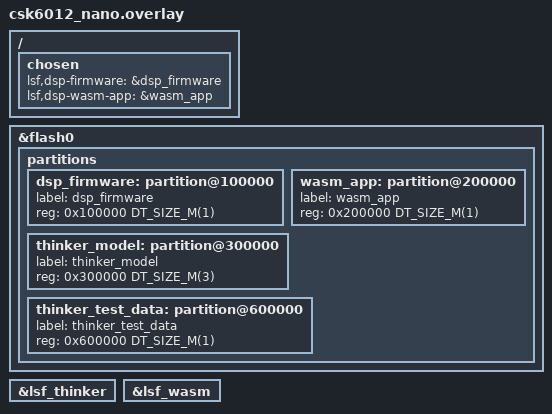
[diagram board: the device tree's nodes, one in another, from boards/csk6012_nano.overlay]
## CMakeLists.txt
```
# Copyright (c) 2023 LISTENAI
# SPDX-License-Identifier: Apache-2.0

cmake_minimum_required(VERSION 3.20.0)

find_package(Zephyr REQUIRED HINTS $ENV{ZEPHYR_BASE})
project(thinker_wasm)

target_sources(app PRIVATE src/main.c)
```

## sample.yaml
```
sample:
  name: thinker_wasm
tests:
  sample.thinker_wasm:
    tags: thinker wasm
```

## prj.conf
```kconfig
CONFIG_HEAP_MEM_POOL_SIZE=204800

CONFIG_CSK_HEAP=y
CONFIG_CSK_HEAP_MEM_POOL_SIZE=40960

CONFIG_FLASH=y
CONFIG_FLASH_MAP=y
CONFIG_FLASH_PAGE_LAYOUT=y

CONFIG_FILE_SYSTEM=y
CONFIG_FILE_SYSTEM_LITTLEFS=y

# CONFIG_CSK6_FLASH_STALL_SECOND_CORE=n
```

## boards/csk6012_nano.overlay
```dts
/*
 * Copyright(c) 2023 LISTENAI
 * SPDX-License-Identifier: Apache-2.0
 */

#include <lsf/lsf.dtsi>

/ {
	chosen {
		lsf,dsp-firmware = &dsp_firmware;
		lsf,dsp-wasm-app = &wasm_app;
	};
};

&flash0 {
	partitions {
		dsp_firmware: partition@100000 {
			label = "dsp_firmware";
			reg = <0x100000 DT_SIZE_M(1)>;
		};

		wasm_app: partition@200000 {
			label = "wasm_app";
			reg = <0x200000 DT_SIZE_M(1)>;
		};

		thinker_model: partition@300000 {
			label = "thinker_model";
			reg = <0x300000 DT_SIZE_M(3)>;
		};

		thinker_test_data: partition@600000 {
			label = "thinker_test_data";
			reg = <0x600000 DT_SIZE_M(1)>;
		};
	};
};

&lsf_thinker {
	status = "okay";
};

&lsf_wasm {
	status = "okay";
};
```

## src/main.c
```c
/*
 * Copyright(c) 2023 LISTENAI
 * SPDX-License-Identifier: Apache-2.0
 */

#include <stdint.h>

#include <zephyr/kernel.h>
#include <zephyr/device.h>
#include <zephyr/storage/flash_map.h>

#include <lsf/services/thinker.h>

#include "apple_input.h"

#define FLASH_ADDR         (DT_REG_ADDR(DT_CHOSEN(zephyr_flash)))
#define THINKER_MODEL_ADDR (FLASH_ADDR + FLASH_AREA_OFFSET(thinker_model))

#define THINKER_TEST_DATA_ADDR    (FLASH_ADDR + FLASH_AREA_OFFSET(thinker_test_data))
#define THINKER_TEST_OUTPUT_COUNT (10)

void main(void)
{
	printk("Hello World! %s\n", CONFIG_BOARD);

	/* 加载 Thinker 模型，注意传入模型的实际字节数 */
	lsf_thinker_set_model((const void *)THINKER_MODEL_ADDR, 436224);
	printk("Model loaded\n");

	int8_t *outputs[THINKER_TEST_OUTPUT_COUNT];
	uint32_t output_sizes[THINKER_TEST_OUTPUT_COUNT];

	/*
	 * 在实际应用中你可能需要持续不断地输入数据，这里仅用一个循环来演示。
	 * 请根据实际情况修改。
	 */
	for (uint32_t i = 0;; i++) {
		k_msleep(200);
		printk("========== LOOP %d ==========\n", i);

		printk("setInput, size: %d\n", input_resource_len);
		lsf_thinker_set_input((const void *)THINKER_TEST_DATA_ADDR, 98304);

		int count = lsf_thinker_get_output_count();
		printk("getOutputCount, count: %d\n", count);

		lsf_thinker_get_output((void **)outputs, output_sizes);
		for (int i = 0; i < count; i++) {
			printk("getOutput, index: %d, ptr: %p, size: %d\n", i, outputs[i],
			       output_sizes[i]);
		}
	}
}
```
